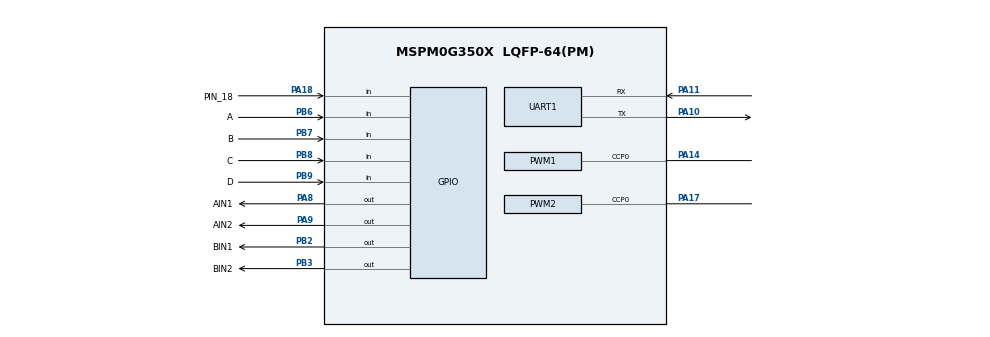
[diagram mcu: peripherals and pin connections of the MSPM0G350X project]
/**
 * @cliArgs --device "MSPM0G350X" --package "LQFP-64(PM)" --part "Default" --product "mspm0_sdk@2.01.00.03"
 * @versions {"tool":"1.19.0+3426"}
 */

/**
 * Import the modules used in this configuration.
 */
const GPIO    = scripting.addModule("/ti/driverlib/GPIO", {}, false);
const GPIO1   = GPIO.addInstance();
const GPIO2   = GPIO.addInstance();
const GPIO3   = GPIO.addInstance();
const GPIO4   = GPIO.addInstance();
const PWM     = scripting.addModule("/ti/driverlib/PWM", {}, false);
const PWM1    = PWM.addInstance();
const PWM2    = PWM.addInstance();
const SYSCTL  = scripting.addModule("/ti/driverlib/SYSCTL");
const SYSTICK = scripting.addModule("/ti/driverlib/SYSTICK");
const TIMER   = scripting.addModule("/ti/driverlib/TIMER", {}, false);
const TIMER1  = TIMER.addInstance();
const TIMER2  = TIMER.addInstance();
const UART    = scripting.addModule("/ti/driverlib/UART", {}, false);
const UART1   = UART.addInstance();

/**
 * Write custom configuration values to the imported modules.
 */
const gate7  = system.clockTree["MFCLKGATE"];
gate7.enable = true;

GPIO1.$name                              = "KEY";
GPIO1.port                               = "PORTA";
GPIO1.associatedPins[0].$name            = "PIN_18";
GPIO1.associatedPins[0].direction        = "INPUT";
GPIO1.associatedPins[0].assignedPin      = "18";
GPIO1.associatedPins[0].internalResistor = "PULL_DOWN";
GPIO1.associatedPins[0].interruptEn      = true;
GPIO1.associatedPins[0].polarity         = "RISE";
GPIO1.associatedPins[0].pin.$assign      = "PA18";

const Board = scripting.addModule("/ti/driverlib/Board", {}, false);

GPIO2.$name                          = "GPIO";
GPIO2.port                           = "PORTA";
GPIO2.associatedPins.create(2);
GPIO2.associatedPins[0].$name        = "AIN1";
GPIO2.associatedPins[0].initialValue = "SET";
GPIO2.associatedPins[0].assignedPin  = "8";
GPIO2.associatedPins[0].pin.$assign  = "PA8";
GPIO2.associatedPins[1].$name        = "AIN2";
GPIO2.associatedPins[1].initialValue = "SET";
GPIO2.associatedPins[1].assignedPin  = "9";
GPIO2.associatedPins[1].pin.$assign  = "PA9";

GPIO3.$name                          = "GPIO_1";
GPIO3.port                           = "PORTB";
GPIO3.associatedPins.create(2);
GPIO3.associatedPins[0].$name        = "BIN1";
GPIO3.associatedPins[0].initialValue = "SET";
GPIO3.associatedPins[0].assignedPin  = "2";
GPIO3.associatedPins[0].pin.$assign  = "PB2";
GPIO3.associatedPins[1].$name        = "BIN2";
GPIO3.associatedPins[1].initialValue = "SET";
GPIO3.associatedPins[1].assignedPin  = "3";
GPIO3.associatedPins[1].pin.$assign  = "PB3";

GPIO4.port                               = "PORTB";
GPIO4.$name                              = "Encoder";
GPIO4.associatedPins.create(4);
GPIO4.associatedPins[0].$name            = "A";
GPIO4.associatedPins[0].direction        = "INPUT";
GPIO4.associatedPins[0].interruptEn      = true;
GPIO4.associatedPins[0].internalResistor = "PULL_UP";
GPIO4.associatedPins[0].polarity         = "RISE_FALL";
GPIO4.associatedPins[0].pin.$assign      = "PB6";
GPIO4.associatedPins[1].$name            = "B";
GPIO4.associatedPins[1].direction        = "INPUT";
GPIO4.associatedPins[1].interruptEn      = true;
GPIO4.associatedPins[1].internalResistor = "PULL_UP";
GPIO4.associatedPins[1].polarity         = "RISE_FALL";
GPIO4.associatedPins[1].pin.$assign      = "PB7";
GPIO4.associatedPins[2].$name            = "C";
GPIO4.associatedPins[2].direction        = "INPUT";
GPIO4.associatedPins[2].interruptEn      = true;
GPIO4.associatedPins[2].internalResistor = "PULL_UP";
GPIO4.associatedPins[2].polarity         = "RISE_FALL";
GPIO4.associatedPins[2].pin.$assign      = "PB8";
GPIO4.associatedPins[3].$name            = "D";
GPIO4.associatedPins[3].direction        = "INPUT";
GPIO4.associatedPins[3].interruptEn      = true;
GPIO4.associatedPins[3].internalResistor = "PULL_UP";
GPIO4.associatedPins[3].polarity         = "RISE_FALL";
GPIO4.associatedPins[3].pin.$assign      = "PB9";

PWM1.$name                              = "PWM";
PWM1.clockDivider                       = 8;
PWM1.timerStartTimer                    = true;
PWM1.ccIndex                            = [0];
PWM1.peripheral.$assign                 = "TIMG12";
PWM1.peripheral.ccp0Pin.$assign         = "PA14";
PWM1.PWM_CHANNEL_0.$name                = "ti_driverlib_pwm_PWMTimerCC0";
PWM1.ccp0PinConfig.direction            = scripting.forceWrite("OUTPUT");
PWM1.ccp0PinConfig.hideOutputInversion  = scripting.forceWrite(false);
PWM1.ccp0PinConfig.onlyInternalResistor = scripting.forceWrite(false);
PWM1.ccp0PinConfig.passedPeripheralType = scripting.forceWrite("Digital");
PWM1.ccp0PinConfig.$name                = "ti_driverlib_gpio_GPIOPinGeneric2";

PWM2.$name                      = "PWM_1";
PWM2.clockDivider               = 8;
PWM2.timerStartTimer            = true;
PWM2.peripheral.$assign         = "TIMG7";
PWM2.peripheral.ccp0Pin.$assign = "PA17";
PWM2.PWM_CHANNEL_0.$name        = "ti_driverlib_pwm_PWMTimerCC1";
PWM2.PWM_CHANNEL_1.$name        = "ti_driverlib_pwm_PWMTimerCC2";
PWM2.ccp0PinConfig.$name        = "ti_driverlib_gpio_GPIOPinGeneric3";
PWM2.ccp1PinConfig.$name        = "ti_driverlib_gpio_GPIOPinGeneric4";

SYSCTL.forceDefaultClkConfig = true;
SYSCTL.clockTreeEn           = true;

SYSTICK.periodEnable      = true;
SYSTICK.systickEnable     = true;
SYSTICK.interruptPriority = "0";
SYSTICK.period            = 32;

TIMER1.$name               = "TIMER_0";
TIMER1.timerClkDiv         = 8;
TIMER1.timerClkPrescale    = 256;
TIMER1.timerPeriod         = "1 ms";
TIMER1.timerStartTimer     = true;
TIMER1.retentionRestoreCnt = true;
TIMER1.interruptPriority   = "1";
TIMER1.interrupts          = ["ZERO"];
TIMER1.peripheral.$assign  = "TIMA1";

TIMER2.$name              = "TIMER_1";
TIMER2.interrupts         = ["ZERO"];
TIMER2.timerMode          = "PERIODIC";
TIMER2.timerPeriod        = "1000 ms";
TIMER2.timerClkDiv        = 8;
TIMER2.timerClkPrescale   = 200;
TIMER2.interruptPriority  = "1";
TIMER2.peripheral.$assign = "TIMA0";

UART1.$name                    = "UART_0";
UART1.uartClkSrc               = "MFCLK";
UART1.enabledInterrupts        = ["RX"];
UART1.peripheral.$assign       = "UART0";
UART1.peripheral.rxPin.$assign = "PA11";
UART1.peripheral.txPin.$assign = "PA10";
UART1.txPinConfig.$name        = "ti_driverlib_gpio_GPIOPinGeneric0";
UART1.rxPinConfig.$name        = "ti_driverlib_gpio_GPIOPinGeneric1";

/**
 * Pinmux solution for unlocked pins/peripherals. This ensures that minor changes to the automatic solver in a future
 * version of the tool will not impact the pinmux you originally saw.  These lines can be completely deleted in order to
 * re-solve from scratch.
 */
Board.peripheral.$suggestSolution          = "DEBUGSS";
Board.peripheral.swclkPin.$suggestSolution = "PA20";
Board.peripheral.swdioPin.$suggestSolution = "PA19";
PWM2.peripheral.ccp1Pin.$suggestSolution   = "PA2";
